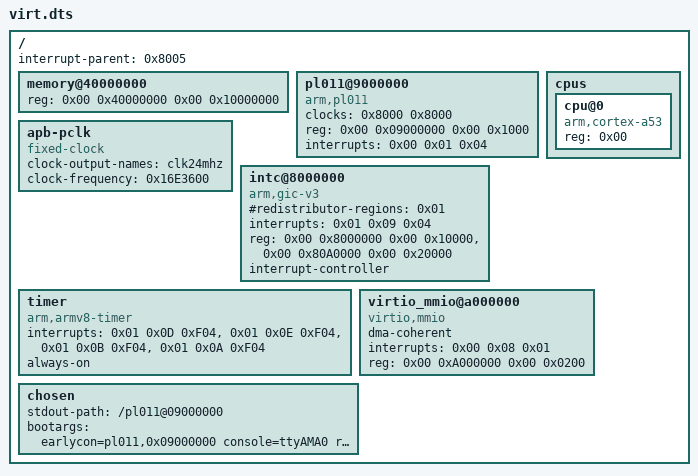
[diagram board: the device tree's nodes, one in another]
/dts-v1/;

/ {
  #size-cells = <0x02>;
  #address-cells = <0x02>;
  interrupt-parent = <0x8005>;

  memory@40000000 {
    device_type = "memory";
    reg = <0x00 0x40000000 0x00 0x10000000>;
  };

  pl011@9000000 {
    compatible = "arm,pl011", "arm,primecell";
    clocks = <0x8000 0x8000>;
    reg = <0x00 0x09000000 0x00 0x1000>;
    interrupts = <0x00 0x01 0x04>;
    clock-names = "uartclk", "apb_pclk";
  };

  cpus {
    #size-cells = <0x00>;
    #address-cells = <0x01>;
    cpu@0 {
      device_type = "cpu";
      compatible = "arm,cortex-a53";
      reg = <0x00>;
      phandle = <0x8004>;
    };
  };

  apb-pclk {
    phandle = <0x8000>;
    compatible = "fixed-clock";
    clock-output-names = "clk24mhz";
    #clock-cells = <0x00>;
    clock-frequency = <0x16E3600>;
  };

  intc@8000000 {
    #interrupt-cells = <0x03>;
    #redistributor-regions = <0x01>;
    compatible = "arm,gic-v3";
    interrupts = <0x01 0x09 0x04>;  // Not used
    reg = <0x00 0x8000000 0x00 0x10000>, // GIC Distributor
          <0x00 0x80A0000 0x00 0x20000>;   // GIC Redistributor
    phandle = <0x8005>;
    interrupt-controller;
  };

  timer {
    interrupts = <0x01 0x0D 0xF04>, <0x01 0x0E 0xF04>, <0x01 0x0B 0xF04>, <0x01 0x0A 0xF04>;
    always-on;
    compatible = "arm,armv8-timer", "arm,armv7-timer";
  };

  virtio_mmio@a000000 {
    dma-coherent;
    compatible = "virtio,mmio";
    interrupts = <0x00 0x08 0x01>;
    reg = <0x00 0xA000000 0x00 0x0200>;
  };

  chosen {
    stdout-path = "/pl011@09000000";
    bootargs = "earlycon=pl011,0x09000000 console=ttyAMA0 root=/dev/vda";
  };
};
